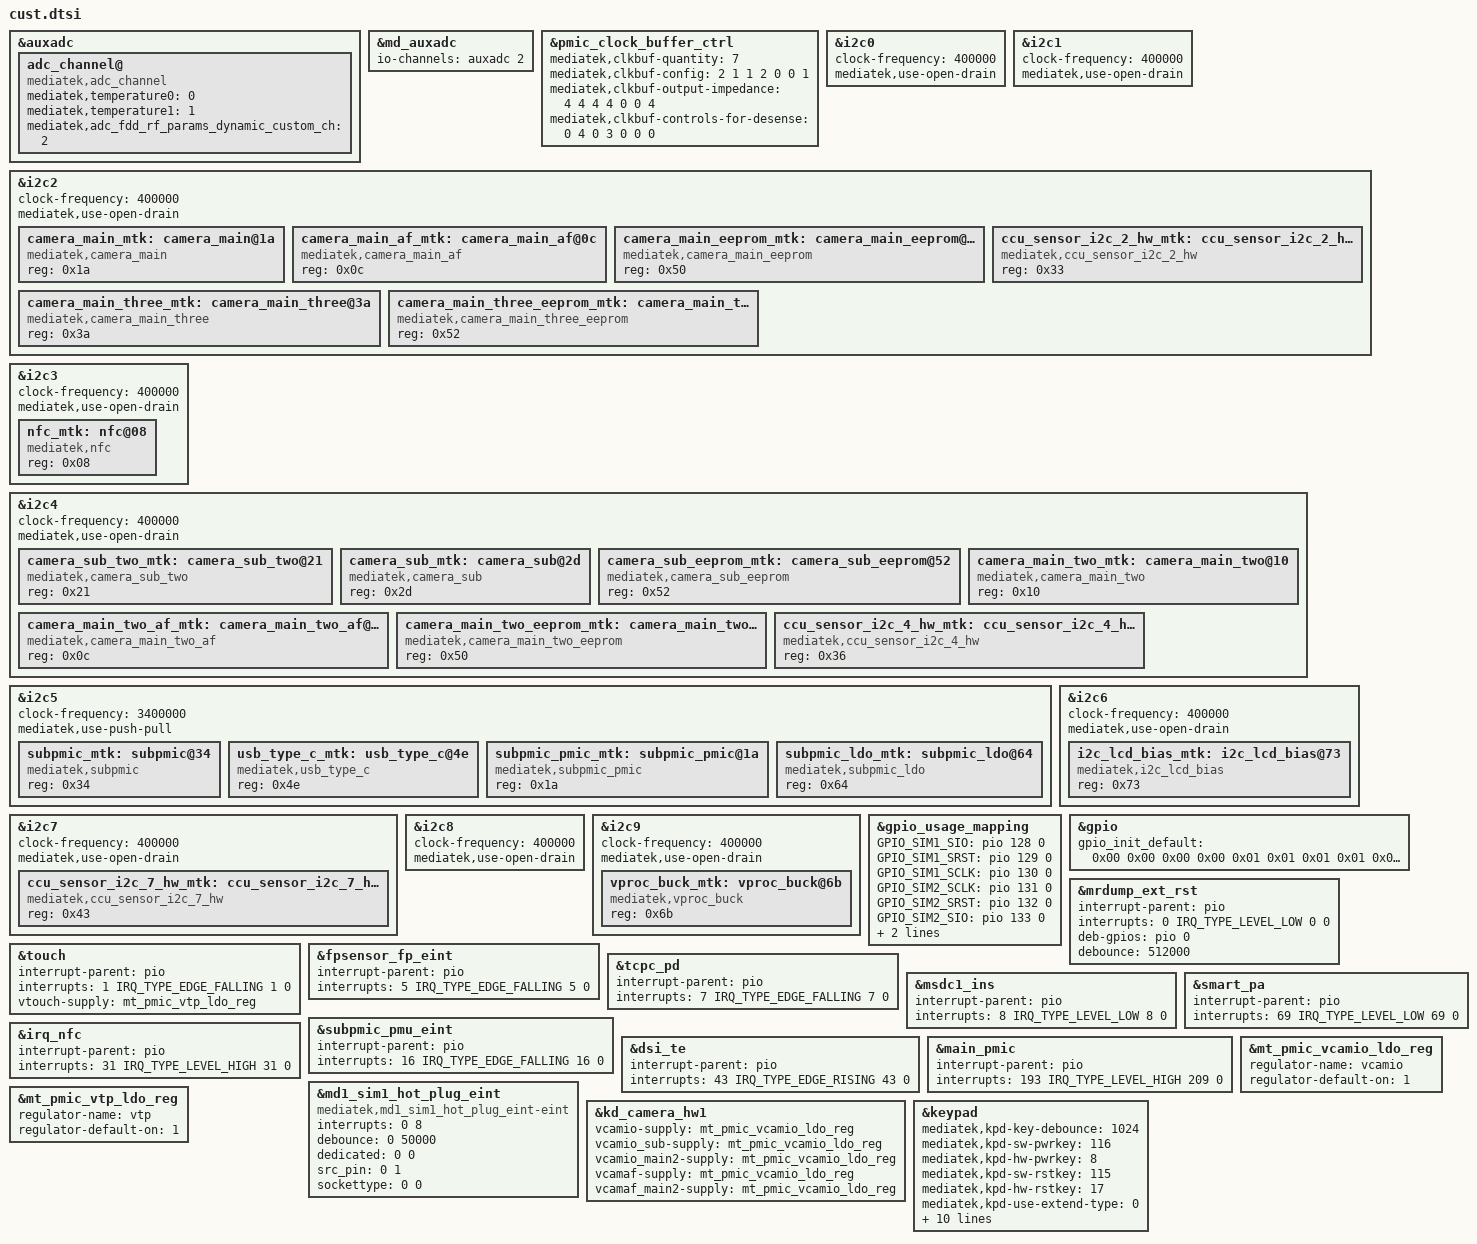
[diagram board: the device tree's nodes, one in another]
/*
 * Generated by MTK SP DrvGen Version: 3.5.160809 for MT6785.
 * 2023-01-07 15:17:33
 * Do Not Modify The File.
 * Copyright Mediatek Inc. (c) 2016.
*/

/*************************
 * ADC DTSI File
*************************/

&auxadc {
	adc_channel@ {
		compatible = "mediatek,adc_channel";
		mediatek,temperature0 = <0>;
		mediatek,temperature1 = <1>;
		mediatek,adc_fdd_rf_params_dynamic_custom_ch = <2>;
		status = "okay";
	};
};
&md_auxadc {
	io-channels = <&auxadc 2>;
};


/*************************
 * CLK_BUF DTSI File
*************************/

&pmic_clock_buffer_ctrl {
	mediatek,clkbuf-quantity = <7>;
	mediatek,clkbuf-config = <2 1 1 2 0 0 1>;
	mediatek,clkbuf-output-impedance = <4 4 4 4 0 0 4>;
	mediatek,clkbuf-controls-for-desense = <0 4 0 3 0 0 0>;
	status = "okay";
};


/*************************
 * I2C DTSI File
*************************/

&i2c0 {
	#address-cells = <1>;
	#size-cells = <0>;
	clock-frequency = <400000>;
	mediatek,use-open-drain;
};

&i2c1 {
	#address-cells = <1>;
	#size-cells = <0>;
	clock-frequency = <400000>;
	mediatek,use-open-drain;
};

&i2c2 {
	#address-cells = <1>;
	#size-cells = <0>;
	clock-frequency = <400000>;
	mediatek,use-open-drain;
	camera_main_mtk:camera_main@1a {
		compatible = "mediatek,camera_main";
		reg = <0x1a>;
		status = "okay";
	};

	camera_main_af_mtk:camera_main_af@0c {
		compatible = "mediatek,camera_main_af";
		reg = <0x0c>;
		status = "okay";
	};

	camera_main_eeprom_mtk:camera_main_eeprom@50 {
		compatible = "mediatek,camera_main_eeprom";
		reg = <0x50>;
		status = "okay";
	};

	ccu_sensor_i2c_2_hw_mtk:ccu_sensor_i2c_2_hw@33 {
		compatible = "mediatek,ccu_sensor_i2c_2_hw";
		reg = <0x33>;
		status = "okay";
	};

	camera_main_three_mtk:camera_main_three@3a {
		compatible = "mediatek,camera_main_three";
		reg = <0x3a>;
		status = "okay";
	};

	camera_main_three_eeprom_mtk:camera_main_three_eeprom@52 {
		compatible = "mediatek,camera_main_three_eeprom";
		reg = <0x52>;
		status = "okay";
	};

};

&i2c3 {
	#address-cells = <1>;
	#size-cells = <0>;
	clock-frequency = <400000>;
	mediatek,use-open-drain;
	nfc_mtk:nfc@08 {
		compatible = "mediatek,nfc";
		reg = <0x08>;
		status = "okay";
	};

};

&i2c4 {
	#address-cells = <1>;
	#size-cells = <0>;
	clock-frequency = <400000>;
	mediatek,use-open-drain;
	camera_sub_two_mtk:camera_sub_two@21 {
		compatible = "mediatek,camera_sub_two";
		reg = <0x21>;
		status = "okay";
	};

	camera_sub_mtk:camera_sub@2d {
		compatible = "mediatek,camera_sub";
		reg = <0x2d>;
		status = "okay";
	};

	camera_sub_eeprom_mtk:camera_sub_eeprom@52 {
		compatible = "mediatek,camera_sub_eeprom";
		reg = <0x52>;
		status = "okay";
	};

	camera_main_two_mtk:camera_main_two@10 {
		compatible = "mediatek,camera_main_two";
		reg = <0x10>;
		status = "okay";
	};

	camera_main_two_af_mtk: camera_main_two_af@0c {
	compatible = "mediatek,camera_main_two_af";
	reg = <0x0c>;
	status = "okay";
	};

	camera_main_two_eeprom_mtk: camera_main_two_eeprom@50 {
	compatible = "mediatek,camera_main_two_eeprom";
	reg = <0x50>;
	status = "okay";
	};

	ccu_sensor_i2c_4_hw_mtk:ccu_sensor_i2c_4_hw@36 {
		compatible = "mediatek,ccu_sensor_i2c_4_hw";
		reg = <0x36>;
		status = "okay";
	};

};

&i2c5 {
	#address-cells = <1>;
	#size-cells = <0>;
	clock-frequency = <3400000>;
	mediatek,use-push-pull;
	subpmic_mtk:subpmic@34 {
		compatible = "mediatek,subpmic";
		reg = <0x34>;
		status = "okay";
	};

	usb_type_c_mtk:usb_type_c@4e {
		compatible = "mediatek,usb_type_c";
		reg = <0x4e>;
		status = "okay";
	};

	subpmic_pmic_mtk:subpmic_pmic@1a {
		compatible = "mediatek,subpmic_pmic";
		reg = <0x1a>;
		status = "okay";
	};

	subpmic_ldo_mtk:subpmic_ldo@64 {
		compatible = "mediatek,subpmic_ldo";
		reg = <0x64>;
		status = "okay";
	};

};

&i2c6 {
	#address-cells = <1>;
	#size-cells = <0>;
	clock-frequency = <400000>;
	mediatek,use-open-drain;
	i2c_lcd_bias_mtk:i2c_lcd_bias@73 {
		compatible = "mediatek,i2c_lcd_bias";
		reg = <0x73>;
		status = "okay";
	};

};

&i2c7 {
	#address-cells = <1>;
	#size-cells = <0>;
	clock-frequency = <400000>;
	mediatek,use-open-drain;
	ccu_sensor_i2c_7_hw_mtk:ccu_sensor_i2c_7_hw@43 {
		compatible = "mediatek,ccu_sensor_i2c_7_hw";
		reg = <0x43>;
		status = "okay";
	};

};

&i2c8 {
	#address-cells = <1>;
	#size-cells = <0>;
	clock-frequency = <400000>;
	mediatek,use-open-drain;
};

&i2c9 {
	#address-cells = <1>;
	#size-cells = <0>;
	clock-frequency = <400000>;
	mediatek,use-open-drain;
	vproc_buck_mtk:vproc_buck@6b {
		compatible = "mediatek,vproc_buck";
		reg = <0x6b>;
		status = "okay";
	};

};



/*************************
 * GPIO DTSI File
*************************/

&gpio_usage_mapping {
	GPIO_SIM1_SIO = <&pio 128 0>;
	GPIO_SIM1_SRST = <&pio 129 0>;
	GPIO_SIM1_SCLK = <&pio 130 0>;
	GPIO_SIM2_SCLK = <&pio 131 0>;
	GPIO_SIM2_SRST = <&pio 132 0>;
	GPIO_SIM2_SIO = <&pio 133 0>;
	GPIO_SIM1_HOT_PLUG = <&pio 140 0>;
	GPIO_SIM2_HOT_PLUG = <&pio 141 0>;
};

&gpio {
	gpio_init_default = <0x00 0x00 0x00 0x00 0x01 0x01 0x01 0x01 0x00 0x00 0x00 0x01 0x01 0x01 0x02 0x00 0x01 0x00 0x00 0x00 0x01 0x03 0x07 0x00 0x00 0x01 0x00 0x01 0x04 0x00 0x00 0x00 0x01 0x00 0x01 0x05 0x00 0x00 0x00 0x01 0x01 0x01 0x06 0x00 0x00 0x00 0x01 0x00 0x01 0x07 0x00 0x00 0x00 0x01 0x01 0x01 0x08 0x00 0x00 0x00 0x01 0x01 0x01 0x09 0x00 0x00 0x00 0x01 0x00 0x01 0x0a 0x00 0x00 0x00 0x01 0x00 0x01 0x0b 0x00 0x00 0x00 0x01 0x01 0x01 0x0c 0x00 0x00 0x00 0x01 0x01 0x00 0x0d 0x00 0x01 0x00 0x00 0x00 0x00 0x0e 0x00 0x01 0x00 0x00 0x00 0x00 0x0f 0x00 0x01 0x00 0x00 0x00 0x00 0x10 0x00 0x00 0x00 0x01 0x01 0x01 0x11 0x01 0x00 0x00 0x01 0x00 0x00 0x12 0x01 0x01 0x00 0x00 0x00 0x00 0x13 0x01 0x01 0x00 0x00 0x00 0x00 0x14 0x01 0x01 0x00 0x00 0x00 0x00 0x15 0x00 0x01 0x00 0x00 0x00 0x00 0x16 0x00 0x01 0x00 0x00 0x00 0x00 0x17 0x00 0x01 0x00 0x00 0x00 0x00 0x18 0x00 0x01 0x00 0x00 0x00 0x00 0x19 0x01 0x00 0x00 0x01 0x00 0x00 0x1a 0x01 0x01 0x00 0x00 0x00 0x00 0x1c 0x01 0x00 0x00 0x01 0x01 0x01 0x1d 0x01 0x00 0x00 0x01 0x01 0x01 0x1e 0x00 0x01 0x00 0x00 0x00 0x00 0x1f 0x00 0x00 0x00 0x01 0x00 0x00 0x20 0x00 0x01 0x00 0x01 0x01 0x00 0x21 0x00 0x00 0x00 0x01 0x00 0x00 0x22 0x00 0x01 0x00 0x00 0x00 0x00 0x23 0x06 0x00 0x00 0x01 0x00 0x00 0x24 0x06 0x00 0x00 0x00 0x00 0x00 0x25 0x06 0x00 0x00 0x01 0x00 0x00 0x26 0x06 0x01 0x00 0x00 0x00 0x00 0x27 0x06 0x00 0x00 0x01 0x00 0x00 0x28 0x06 0x00 0x00 0x01 0x00 0x00 0x29 0x06 0x00 0x00 0x01 0x00 0x00 0x2a 0x01 0x01 0x00 0x00 0x00 0x00 0x2b 0x00 0x00 0x00 0x01 0x00 0x00 0x2c 0x00 0x01 0x00 0x00 0x00 0x00 0x2d 0x01 0x00 0x00 0x01 0x01 0x01 0x2e 0x01 0x00 0x00 0x01 0x01 0x01 0x2f 0x01 0x00 0x00 0x01 0x00 0x00 0x30 0x01 0x01 0x00 0x00 0x00 0x00 0x31 0x01 0x01 0x00 0x00 0x00 0x00 0x32 0x01 0x01 0x00 0x00 0x00 0x00 0x33 0x01 0x00 0x00 0x01 0x01 0x01 0x34 0x01 0x00 0x00 0x01 0x01 0x01 0x35 0x01 0x00 0x00 0x01 0x01 0x00 0x36 0x01 0x01 0x01 0x00 0x00 0x00 0x37 0x01 0x00 0x00 0x01 0x01 0x01 0x38 0x01 0x00 0x00 0x01 0x01 0x01 0x39 0x00 0x00 0x00 0x01 0x00 0x00 0x3a 0x00 0x00 0x00 0x01 0x00 0x00 0x3b 0x01 0x00 0x00 0x01 0x01 0x00 0x3c 0x01 0x00 0x00 0x01 0x01 0x00 0x3d 0x02 0x00 0x00 0x01 0x01 0x01 0x3e 0x02 0x00 0x00 0x01 0x01 0x01 0x3f 0x02 0x00 0x00 0x01 0x00 0x00 0x40 0x02 0x01 0x00 0x00 0x00 0x00 0x41 0x02 0x01 0x00 0x00 0x00 0x00 0x42 0x02 0x01 0x00 0x00 0x00 0x00 0x43 0x00 0x01 0x01 0x01 0x00 0x00 0x44 0x00 0x00 0x00 0x00 0x00 0x00 0x45 0x00 0x00 0x00 0x01 0x01 0x01 0x46 0x00 0x00 0x00 0x00 0x00 0x00 0x47 0x00 0x00 0x00 0x00 0x00 0x00 0x48 0x00 0x00 0x00 0x00 0x00 0x00 0x49 0x00 0x00 0x00 0x00 0x00 0x00 0x4a 0x03 0x00 0x00 0x01 0x00 0x00 0x4b 0x00 0x00 0x00 0x00 0x00 0x00 0x4c 0x01 0x00 0x00 0x01 0x00 0x00 0x4d 0x01 0x00 0x00 0x01 0x00 0x00 0x4e 0x01 0x00 0x00 0x01 0x00 0x00 0x4f 0x01 0x00 0x00 0x01 0x00 0x00 0x50 0x01 0x00 0x00 0x01 0x00 0x00 0x51 0x01 0x00 0x00 0x01 0x00 0x00 0x52 0x01 0x00 0x00 0x01 0x00 0x00 0x53 0x01 0x00 0x00 0x01 0x00 0x00 0x54 0x01 0x00 0x00 0x01 0x00 0x00 0x55 0x01 0x00 0x00 0x01 0x00 0x00 0x56 0x01 0x00 0x00 0x01 0x00 0x00 0x57 0x01 0x00 0x00 0x01 0x00 0x00 0x58 0x01 0x00 0x00 0x01 0x00 0x00 0x59 0x01 0x00 0x00 0x01 0x00 0x00 0x5a 0x01 0x00 0x00 0x01 0x00 0x00 0x5b 0x01 0x00 0x00 0x01 0x00 0x00 0x5c 0x01 0x00 0x00 0x01 0x00 0x00 0x5d 0x01 0x00 0x00 0x01 0x00 0x00 0x5e 0x01 0x00 0x00 0x01 0x00 0x00 0x5f 0x01 0x00 0x00 0x01 0x00 0x00 0x60 0x01 0x00 0x00 0x01 0x00 0x00 0x61 0x01 0x00 0x00 0x01 0x00 0x00 0x62 0x01 0x00 0x00 0x01 0x00 0x00 0x63 0x01 0x00 0x00 0x01 0x00 0x00 0x64 0x01 0x00 0x00 0x01 0x00 0x00 0x65 0x01 0x00 0x00 0x01 0x00 0x00 0x66 0x01 0x00 0x00 0x01 0x00 0x00 0x67 0x01 0x00 0x00 0x01 0x00 0x00 0x68 0x01 0x00 0x00 0x01 0x00 0x00 0x69 0x01 0x00 0x00 0x01 0x00 0x00 0x6a 0x01 0x00 0x00 0x01 0x00 0x00 0x6b 0x01 0x00 0x00 0x01 0x00 0x00 0x6c 0x01 0x00 0x00 0x01 0x00 0x00 0x6d 0x01 0x00 0x00 0x01 0x00 0x00 0x6e 0x01 0x00 0x00 0x01 0x01 0x01 0x6f 0x01 0x00 0x00 0x01 0x01 0x01 0x70 0x01 0x00 0x00 0x01 0x01 0x01 0x71 0x01 0x00 0x00 0x01 0x01 0x01 0x72 0x00 0x01 0x00 0x00 0x00 0x00 0x73 0x00 0x01 0x00 0x00 0x00 0x00 0x74 0x01 0x01 0x00 0x00 0x00 0x00 0x75 0x01 0x01 0x00 0x00 0x00 0x00 0x76 0x00 0x01 0x00 0x00 0x00 0x00 0x77 0x00 0x01 0x00 0x00 0x00 0x00 0x78 0x01 0x01 0x00 0x00 0x00 0x00 0x79 0x01 0x01 0x00 0x00 0x00 0x00 0x7a 0x00 0x01 0x00 0x00 0x00 0x00 0x7b 0x00 0x01 0x00 0x00 0x00 0x00 0x7c 0x00 0x01 0x00 0x00 0x00 0x00 0x7d 0x00 0x01 0x00 0x00 0x00 0x00 0x7e 0x00 0x01 0x00 0x00 0x00 0x00 0x7f 0x00 0x01 0x00 0x00 0x00 0x00 0x80 0x01 0x00 0x00 0x01 0x01 0x01 0x81 0x01 0x01 0x00 0x00 0x00 0x01 0x82 0x01 0x01 0x00 0x00 0x00 0x01 0x83 0x01 0x01 0x00 0x00 0x00 0x01 0x84 0x01 0x01 0x00 0x00 0x00 0x01 0x85 0x01 0x00 0x00 0x01 0x01 0x01 0x86 0x01 0x01 0x00 0x00 0x00 0x01 0x87 0x01 0x00 0x00 0x01 0x01 0x01 0x88 0x01 0x00 0x00 0x01 0x01 0x01 0x89 0x01 0x00 0x00 0x01 0x01 0x01 0x8a 0x01 0x00 0x00 0x01 0x01 0x01 0x8b 0x01 0x00 0x00 0x01 0x01 0x01 0x8c 0x01 0x00 0x00 0x01 0x01 0x01 0x8d 0x01 0x00 0x00 0x01 0x01 0x01 0x8e 0x01 0x01 0x00 0x00 0x00 0x00 0x8f 0x01 0x01 0x00 0x00 0x00 0x01 0x90 0x01 0x01 0x00 0x00 0x00 0x01 0x91 0x01 0x01 0x00 0x00 0x00 0x01 0x92 0x01 0x00 0x00 0x01 0x00 0x01 0x93 0x00 0x00 0x00 0x01 0x00 0x00 0x94 0x00 0x00 0x00 0x01 0x00 0x00 0x95 0x00 0x00 0x00 0x01 0x00 0x00 0x96 0x01 0x01 0x00 0x00 0x00 0x00 0x97 0x01 0x00 0x00 0x01 0x01 0x01 0x98 0x01 0x00 0x00 0x01 0x01 0x01 0x99 0x00 0x00 0x00 0x01 0x00 0x00 0x9a 0x00 0x00 0x00 0x01 0x00 0x00 0x9b 0x00 0x01 0x00 0x00 0x00 0x00 0x9c 0x00 0x01 0x00 0x00 0x00 0x00 0x9d 0x00 0x01 0x00 0x00 0x00 0x00 0x9e 0x00 0x01 0x00 0x00 0x00 0x00 0x9f 0x00 0x01 0x00 0x00 0x00 0x00 0xa0 0x00 0x01 0x00 0x00 0x00 0x00 0xa1 0x00 0x01 0x00 0x00 0x00 0x00 0xa2 0x00 0x01 0x00 0x00 0x00 0x00 0xa3 0x00 0x01 0x00 0x00 0x00 0x00 0xa4 0x00 0x01 0x00 0x00 0x00 0x00 0xa5 0x00 0x00 0x00 0x01 0x00 0x00 0xa6 0x00 0x00 0x00 0x01 0x00 0x00 0xb3 0x01 0x00 0x00 0x01 0x00 0x00 0xb4 0x01 0x00 0x00 0x01 0x00 0x00 0xb5 0x01 0x01 0x00 0x00 0x00 0x00 0xb6 0x01 0x01 0x00 0x00 0x00 0x00 0xb7 0x01 0x01 0x00 0x00 0x00 0x00 0xb8 0x01 0x00 0x00 0x01 0x00 0x00 0xb9 0x01 0x01 0x00 0x00 0x00 0x00 0xba 0x01 0x00 0x00 0x01 0x00 0x00 0xbb 0x01 0x01 0x00 0x00 0x00 0x00 0xbc 0x01 0x00 0x00 0x01 0x00 0x01 0xbd 0x01 0x01 0x00 0x00 0x00 0x01 0xbe 0x01 0x01 0x00 0x00 0x00 0x01 0xbf 0x01 0x01 0x00 0x00 0x00 0x01 0xc0 0x01 0x01 0x00 0x00 0x00 0x01 0xc1 0x01 0x00 0x00 0x01 0x00 0x01 0xc2 0x01 0x00 0x00 0x01 0x00 0x01 0xc3 0x00 0x01 0x00 0x00 0x00 0x00 0xc4 0x01 0x01 0x00 0x00 0x00 0x00 0xc5 0x00 0x01 0x00 0x00 0x00 0x00 0xc6 0x01 0x00 0x00 0x01 0x01 0x01 0xc7 0x01 0x00 0x00 0x01 0x01 0x01 0xc8 0x01 0x00 0x00 0x01 0x01 0x00 0xc9 0x01 0x01 0x00 0x00 0x00 0x00 0xca 0x00 0x01 0x00 0x00 0x00 0x00 0xcb 0x00 0x00 0x00 0x01 0x00 0x00 0xcc 0x00 0x00 0x00 0x01 0x00 0x00 0xcd 0x00 0x00 0x00 0x01 0x00 0x00 0xce 0x00 0x00 0x00 0x01 0x00 0x00 0xcf 0x00 0x00 0x00 0x01 0x00 0x00 0xd0 0x00 0x00 0x00 0x01 0x00 0x00 0xd1 0x00 0x00 0x00 0x01 0x00 0x00 0xd2 0x00 0x00 0x00 0x01 0x00 0x00>;
};

/*************************
 * EINT DTSI File
*************************/

#include <dt-bindings/interrupt-controller/irq.h>
#include <dt-bindings/interrupt-controller/arm-gic.h>

&mrdump_ext_rst {
	interrupt-parent = <&pio>;
	interrupts = <0 IRQ_TYPE_LEVEL_LOW 0 0>;
	deb-gpios = <&pio 0 0>;
	debounce = <512000>;
	status = "okay";
};

&touch {
	interrupt-parent = <&pio>;
	interrupts = <1 IRQ_TYPE_EDGE_FALLING 1 0>;
	status = "okay";
};

&fpsensor_fp_eint {
	interrupt-parent = <&pio>;
	interrupts = <5 IRQ_TYPE_EDGE_FALLING 5 0>;
	status = "okay";
};

&tcpc_pd {
	interrupt-parent = <&pio>;
	interrupts = <7 IRQ_TYPE_EDGE_FALLING 7 0>;
	status = "okay";
};

&msdc1_ins {
	interrupt-parent = <&pio>;
	interrupts = <8 IRQ_TYPE_LEVEL_LOW 8 0>;
	status = "okay";
};

&subpmic_pmu_eint {
	interrupt-parent = <&pio>;
	interrupts = <16 IRQ_TYPE_EDGE_FALLING 16 0>;
	status = "okay";
};

&irq_nfc {
	interrupt-parent = <&pio>;
	interrupts = <31 IRQ_TYPE_LEVEL_HIGH 31 0>;
	status = "okay";
};

&dsi_te {
	interrupt-parent = <&pio>;
	interrupts = <43 IRQ_TYPE_EDGE_RISING 43 0>;
	status = "okay";
};

&smart_pa {
	interrupt-parent = <&pio>;
	interrupts = <69 IRQ_TYPE_LEVEL_LOW 69 0>;
	status = "okay";
};

&main_pmic {
	interrupt-parent = <&pio>;
	interrupts = <193 IRQ_TYPE_LEVEL_HIGH 209 0>;
	status = "okay";
};



/*************************
 * MD1_EINT DTSI File
*************************/

&md1_sim1_hot_plug_eint {
	compatible = "mediatek,md1_sim1_hot_plug_eint-eint";
	interrupts = <0 8>;
	debounce = <0 50000>;
	dedicated = <0 0>;
	src_pin = <0 1>;
	sockettype = <0 0>;
	status = "okay";
};



/*************************
 * PMIC DTSI File
*************************/

&mt_pmic_vcamio_ldo_reg {
	regulator-name = "vcamio";
	regulator-default-on = <1>; /* 0:skip, 1: off, 2:on */
	status = "okay";
};
&mt_pmic_vtp_ldo_reg {
	regulator-name = "vtp";
	regulator-default-on = <1>; /* 0:skip, 1: off, 2:on */
	status = "okay";
};

&kd_camera_hw1 {
	vcamio-supply = <&mt_pmic_vcamio_ldo_reg>;
	vcamio_sub-supply = <&mt_pmic_vcamio_ldo_reg>;
	vcamio_main2-supply = <&mt_pmic_vcamio_ldo_reg>;
	vcamaf-supply = <&mt_pmic_vcamio_ldo_reg>;
	vcamaf_main2-supply = <&mt_pmic_vcamio_ldo_reg>;
	status = "okay";
};

&touch {
	vtouch-supply = <&mt_pmic_vtp_ldo_reg>;
	status = "okay";
};


/*************************
 * POWER DTSI File
*************************/



/*************************
 * KPD DTSI File
*************************/

&keypad {
	mediatek,kpd-key-debounce = <1024>;
	mediatek,kpd-sw-pwrkey = <116>;
	mediatek,kpd-hw-pwrkey = <8>;
	mediatek,kpd-sw-rstkey  = <115>;
	mediatek,kpd-hw-rstkey = <17>;
	mediatek,kpd-use-extend-type = <0>;
	/*HW Keycode [0~71] -> Linux Keycode*/
	mediatek,kpd-hw-map-num = <72>;
	mediatek,kpd-hw-init-map = <114 0 0 0 0 0 0 0 0 0 0 0 0 0 0 0 0 0 0 0 0 0 0 0 0 0 0 0 0 0 0 0 0 0 0 0 0 0 0 0 0 0 0 0 0 0 0 0 0 0 0 0 0 0 0 0 0 0 0 0 0 0 0 0 0 0 0 0 0 0 0 0 >;
	mediatek,kpd-pwrkey-eint-gpio = <0>;
	mediatek,kpd-pwkey-gpio-din  = <0>;
	mediatek,kpd-hw-dl-key0 = <17>;
	mediatek,kpd-hw-dl-key1 = <0>;
	mediatek,kpd-hw-dl-key2 = <8>;
	mediatek,kpd-hw-recovery-key = <17>;
	mediatek,kpd-hw-factory-key = <0>;
	status = "okay";
};


